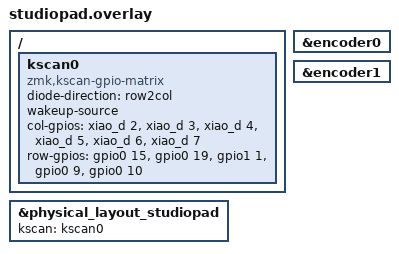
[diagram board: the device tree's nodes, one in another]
#include "studiopad.dtsi"

/ {
    kscan0: kscan0 {
        compatible = "zmk,kscan-gpio-matrix";
        diode-direction = "row2col";
        wakeup-source;

        col-gpios
            = <&xiao_d 2 (GPIO_ACTIVE_HIGH | GPIO_PULL_DOWN)>
            , <&xiao_d 3 (GPIO_ACTIVE_HIGH | GPIO_PULL_DOWN)>
            , <&xiao_d 4 (GPIO_ACTIVE_HIGH | GPIO_PULL_DOWN)>
            , <&xiao_d 5 (GPIO_ACTIVE_HIGH | GPIO_PULL_DOWN)>
            , <&xiao_d 6 (GPIO_ACTIVE_HIGH | GPIO_PULL_DOWN)>
            , <&xiao_d 7 (GPIO_ACTIVE_HIGH | GPIO_PULL_DOWN)>
            ;

        row-gpios
            = <&gpio0 15 GPIO_ACTIVE_HIGH>
            , <&gpio0 19 GPIO_ACTIVE_HIGH>
            , <&gpio1 1 GPIO_ACTIVE_HIGH>
            , <&gpio0 9 GPIO_ACTIVE_HIGH>
            , <&gpio0 10 GPIO_ACTIVE_HIGH>
            ;
    };
};

&physical_layout_studiopad {
    kscan = <&kscan0>;
};

&encoder0 {
    status = "okay";
};
&encoder1 {
    status = "okay";
};

